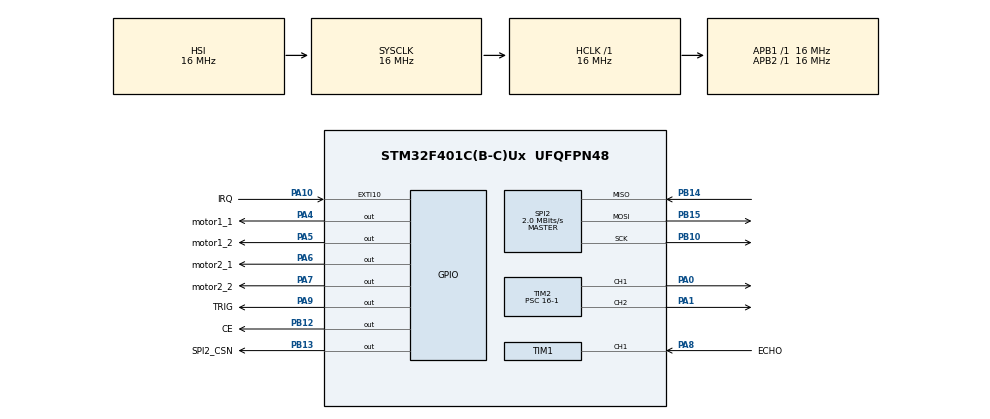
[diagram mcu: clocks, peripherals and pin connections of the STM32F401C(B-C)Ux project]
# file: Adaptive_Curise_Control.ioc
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Mcu.Family=STM32F4
Mcu.Name=STM32F401C(B-C)Ux
Mcu.Package=UFQFPN48
NVIC.EXTI15_10_IRQn=true\:0\:0\:false\:false\:true\:true\:true\:true
NVIC.PriorityGroup=NVIC_PRIORITYGROUP_4
NVIC.TIM1_CC_IRQn=true\:0\:0\:false\:false\:true\:true\:true\:true
PA0-WKUP.Signal=S_TIM2_CH1_ETR
PA1.Signal=S_TIM2_CH2
PA10.GPIO_Label=IRQ
PA10.Signal=GPXTI10
PA4.GPIO_Label=motor1_1
PA4.Signal=GPIO_Output
PA5.GPIO_Label=motor1_2
PA5.Signal=GPIO_Output
PA6.GPIO_Label=motor2_1
PA6.Signal=GPIO_Output
PA7.GPIO_Label=motor2_2
PA7.Signal=GPIO_Output
PA8.GPIO_Label=ECHO
PA8.Signal=S_TIM1_CH1
PA9.GPIO_Label=TRIG
PA9.Signal=GPIO_Output
PB10.Mode=Full_Duplex_Master
PB10.Signal=SPI2_SCK
PB12.GPIO_Label=CE
PB12.Signal=GPIO_Output
PB13.GPIO_Label=SPI2_CSN
PB13.Signal=GPIO_Output
PB14.Mode=Full_Duplex_Master
PB14.Signal=SPI2_MISO
PB15.Mode=Full_Duplex_Master
PB15.Signal=SPI2_MOSI
ProjectManager.HeapSize=0x200
ProjectManager.StackSize=0x400
ProjectManager.TargetToolchain=STM32CubeIDE
RCC.AHBFreq_Value=16000000
RCC.APB1Freq_Value=16000000
RCC.APB2Freq_Value=16000000
RCC.CortexFreq_Value=16000000
RCC.HSE_VALUE=25000000
RCC.HSI_VALUE=16000000
RCC.LSE_VALUE=32768
RCC.SYSCLKFreq_VALUE=16000000
RCC.VCOOutputFreq_Value=192000000
SH.S_TIM1_CH1.0=TIM1_CH1,Input_Capture1_from_TI1
SH.S_TIM2_CH1_ETR.0=TIM2_CH1,PWM Generation1 CH1
SH.S_TIM2_CH2.0=TIM2_CH2,PWM Generation2 CH2
SPI2.BaudRatePrescaler=SPI_BAUDRATEPRESCALER_8
SPI2.CalculateBaudRate=2.0 MBits/s
SPI2.Direction=SPI_DIRECTION_2LINES
SPI2.Mode=SPI_MODE_MASTER
SPI2.VirtualType=VM_MASTER
TIM1.Channel-Input_Capture1_from_TI1=TIM_CHANNEL_1
TIM1.Period=0xffff-1
TIM1.Prescaler=16-1
TIM2.Channel-PWM\ Generation1\ CH1=TIM_CHANNEL_1
TIM2.Channel-PWM\ Generation2\ CH2=TIM_CHANNEL_2
TIM2.Period=100-1
TIM2.Prescaler=16-1
board=custom

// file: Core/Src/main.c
/* USER CODE BEGIN Header */
/**
  ******************************************************************************
  * @file           : main.c
  * @brief          : Main program body
  ******************************************************************************
  * @attention
  *
  * Copyright (c) 2024 STMicroelectronics.
  * All rights reserved.
  *
  * This software is licensed under terms that can be found in the LICENSE file
  * in the root directory of this software component.
  * If no LICENSE file comes with this software, it is provided AS-IS.
  *
  ******************************************************************************
  */
/* USER CODE END Header */
#include "main.h"
#include "spi.h"
#include "tim.h"
#include "gpio.h"
#include "ACC_interface.h"
#include "DCM_Interface.h"

void SystemClock_Config(void);

int main(void)
{

  /* MCU Configuration--------------------------------------------------------*/

  /* Reset of all peripherals, Initializes the Flash interface and the Systick. */
  HAL_Init();

  /* Configure the system clock */
  SystemClock_Config();

  /* Initialize all configured peripherals */
  MX_GPIO_Init();
  MX_TIM2_Init();
  MX_SPI2_Init();
  MX_TIM1_Init();
  /* USER CODE BEGIN 2 */
  ACC_voidInit();
  /* USER CODE END 2 */

  /* Infinite loop */
  /* USER CODE BEGIN WHILE */
  while (1)
  {
	  ACC_voidRun();
    /* USER CODE END WHILE */

  }
}

void SystemClock_Config(void)
{
  RCC_OscInitTypeDef RCC_OscInitStruct = {0};
  RCC_ClkInitTypeDef RCC_ClkInitStruct = {0};

  /** Configure the main internal regulator output voltage
  */
  __HAL_RCC_PWR_CLK_ENABLE();
  __HAL_PWR_VOLTAGESCALING_CONFIG(PWR_REGULATOR_VOLTAGE_SCALE2);

  /** Initializes the RCC Oscillators according to the specified parameters
  * in the RCC_OscInitTypeDef structure.
  */
  RCC_OscInitStruct.OscillatorType = RCC_OSCILLATORTYPE_HSI;
  RCC_OscInitStruct.HSIState = RCC_HSI_ON;
  RCC_OscInitStruct.HSICalibrationValue = RCC_HSICALIBRATION_DEFAULT;
  RCC_OscInitStruct.PLL.PLLState = RCC_PLL_NONE;
  if (HAL_RCC_OscConfig(&RCC_OscInitStruct) != HAL_OK)
  {
    Error_Handler();
  }

  /** Initializes the CPU, AHB and APB buses clocks
  */
  RCC_ClkInitStruct.ClockType = RCC_CLOCKTYPE_HCLK|RCC_CLOCKTYPE_SYSCLK
                              |RCC_CLOCKTYPE_PCLK1|RCC_CLOCKTYPE_PCLK2;
  RCC_ClkInitStruct.SYSCLKSource = RCC_SYSCLKSOURCE_HSI;
  RCC_ClkInitStruct.AHBCLKDivider = RCC_SYSCLK_DIV1;
  RCC_ClkInitStruct.APB1CLKDivider = RCC_HCLK_DIV1;
  RCC_ClkInitStruct.APB2CLKDivider = RCC_HCLK_DIV1;

  if (HAL_RCC_ClockConfig(&RCC_ClkInitStruct, FLASH_LATENCY_0) != HAL_OK)
  {
    Error_Handler();
  }
}

void Error_Handler(void)
{
  __disable_irq();
  while (1)
  {
  }
}
